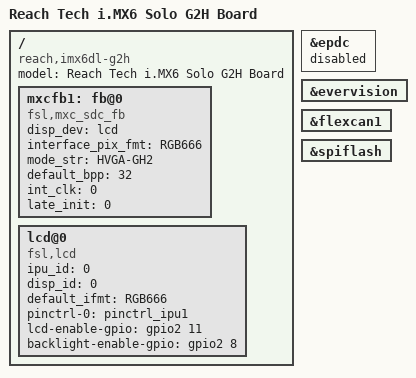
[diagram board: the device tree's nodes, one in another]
/*
 * Author:  Jeff Horn  <jeff.horn@reachtech.com>
 *
 * This program is free software; you can redistribute i	t and/or modify
 * it under the terms of the GNU General Public License version 2 as
 * published by the Free Software Foundation.
 *
 */
/dts-v1/;

#include <dt-bindings/interrupt-controller/irq.h>
#include "imx6dl.dtsi"
#include "imx6qdl-g2h.dtsi"

/ {
	model = "Reach Tech i.MX6 Solo G2H Board";
	compatible = "reach,imx6dl-g2h", "fsl,imx6dl";

	/*
	 * Panel: 6" HVGA
	 * Touch: USB HIB
	 * Display Interface: Parallel
	 */

	mxcfb1: fb@0 {
		compatible = "fsl,mxc_sdc_fb";
		disp_dev = "lcd";
		interface_pix_fmt = "RGB666";
		mode_str ="HVGA-GH2";
		default_bpp = <32>;
		int_clk = <0>;
		late_init = <0>;
		status = "okay";
	};

       lcd@0 {
		compatible = "fsl,lcd";
		ipu_id = <0>;
		disp_id = <0>;
		default_ifmt = "RGB666";
		pinctrl-names = "default";
		pinctrl-0 = <&pinctrl_ipu1>;
		lcd-enable-gpio = <&gpio2 11 0>;
		backlight-enable-gpio = <&gpio2 8 0>;
		status = "okay";
	};
};

&epdc {
	status = "disabled";
};

&evervision {
	status = "okay";
};

&flexcan1 {
	status = "okay";
};

&spiflash {
	status = "okay";
};
